# STM32L162 register map
File version: 1.3
CPU: CM3 r1p1, little endian, no MPU, no FPU, 4 interrupt priority bits
Registers are 32-bit, read-write, reset 0x0 unless marked. A register's access mark holds for its fields unless they carry their own. Offsets are from the block's base; [hi:lo] are bit positions; {n}, {i} and the like mark numbered series; 'fields as' and 'values as' point back to an identical list.

## DMA1 — Direct memory access controller
Base 0x40026000
Same registers: DMA2 0x40026400
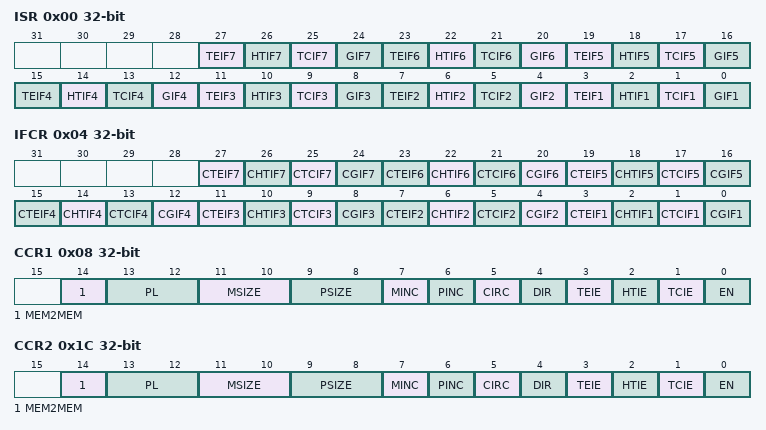
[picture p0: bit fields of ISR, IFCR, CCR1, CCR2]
0x00 ISR ro — interrupt status register
  [4n-1] TEIF{n} (n=1..7) — Channel x transfer error flag (x = 1 ..7)
  [4n-2] HTIF{n} (n=1..7) — Channel x half transfer flag (x = 1 ..7)
  [4n-3] TCIF{n} (n=1..7) — Channel x transfer complete flag (x = 1 ..7)
  [4n-4] GIF{n} (n=1..7) — Channel x global interrupt flag (x = 1 ..7)
0x04 IFCR wo — interrupt flag clear register
  [4n-1] CTEIF{n} (n=1..7) — Channel x transfer error clear (x = 1 ..7)
  [4n-2] CHTIF{n} (n=1..7) — Channel x half transfer clear (x = 1 ..7)
  [4n-3] CTCIF{n} (n=1..7) — Channel x transfer complete clear (x = 1 ..7)
  [4n-4] CGIF{n} (n=1..7) — Channel x global interrupt clear (x = 1 ..7)
0x08 CCR1 — channel x configuration register
  [14] MEM2MEM — Memory to memory mode
  [13:12] PL — Channel priority level
  [11:10] MSIZE — Memory size
  [9:8] PSIZE — Peripheral size
  [7] MINC — Memory increment mode
  [6] PINC — Peripheral increment mode
  [5] CIRC — Circular mode
  [4] DIR — Data transfer direction
  [3] TEIE — Transfer error interrupt enable
  [2] HTIE — Half transfer interrupt enable
  [1] TCIE — Transfer complete interrupt enable
  [0] EN — Channel enable
0x0C CNDTR1 — channel x number of data register
  [15:0] NDT — Number of data to transfer
0x10 CPAR1 — channel x peripheral address register
  [31:0] PA — Peripheral address
{0x0+0x14*i} CMAR{i} (i=1..7) — channel x memory address register
  [31:0] MA — Memory address
0x1C CCR2 — channel x configuration register
  fields as CCR1
0x20 CNDTR2 — channel x number of data register
  [15:0] NDT — Number of data to transfer
0x24 CPAR2 — channel x peripheral address register
  [31:0] PA — Peripheral address
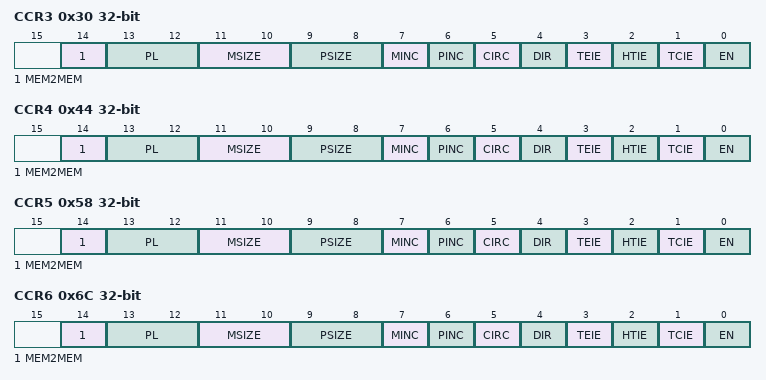
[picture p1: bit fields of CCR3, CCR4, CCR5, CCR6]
0x30 CCR3 — channel x configuration register
  fields as CCR1
0x34 CNDTR3 — channel x number of data register
  [15:0] NDT — Number of data to transfer
0x38 CPAR3 — channel x peripheral address register
  [31:0] PA — Peripheral address
0x44 CCR4 — channel x configuration register
  fields as CCR1
0x48 CNDTR4 — channel x number of data register
  [15:0] NDT — Number of data to transfer
0x4C CPAR4 — channel x peripheral address register
  [31:0] PA — Peripheral address
0x58 CCR5 — channel x configuration register
  fields as CCR1
0x5C CNDTR5 — channel x number of data register
  [15:0] NDT — Number of data to transfer
0x60 CPAR5 — channel x peripheral address register
  [31:0] PA — Peripheral address
0x6C CCR6 — channel x configuration register
  fields as CCR1
0x70 CNDTR6 — channel x number of data register
  [15:0] NDT — Number of data to transfer
0x74 CPAR6 — channel x peripheral address register
  [31:0] PA — Peripheral address
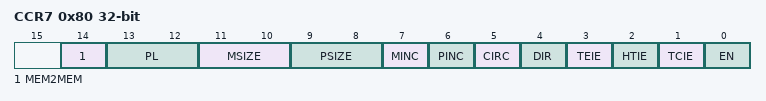
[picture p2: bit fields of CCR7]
0x80 CCR7 — channel x configuration register
  fields as CCR1
0x84 CNDTR7 — channel x number of data register
  [15:0] NDT — Number of data to transfer
0x88 CPAR7 — channel x peripheral address register
  [31:0] PA — Peripheral address

## EXTI — External interrupt/event controller
Base 0x40010400
0x00 IMR
  [22:0] MR — Interrupt mask on line x
0x04 EMR
  [22:0] MR — Event mask on line x
0x08 RTSR
  [22:0] TR — Rising edge trigger event configuration bit of line x
0x0C FTSR
  [22:0] TR — Falling edge trigger event configuration bit of line x
0x10 SWIER
  [22:0] SWIER — Software interrupt on line x
0x14 PR
  [22:0] PR — Pending bit

## Flash
Base 0x40023C00
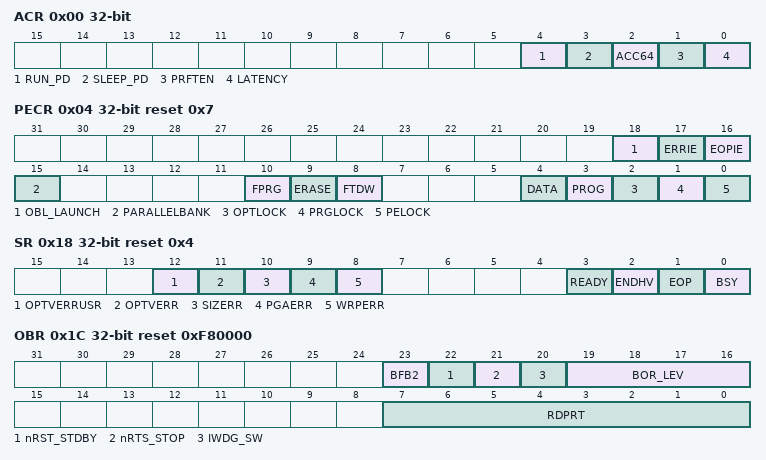
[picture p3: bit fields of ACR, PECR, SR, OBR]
0x00 ACR — Access control register
  [4] RUN_PD — Flash mode during Run
  [3] SLEEP_PD — Flash mode during Sleep
  [2] ACC64 — 64-bit access
  [1] PRFTEN — Prefetch enable
  [0] LATENCY
0x04 PECR reset 0x7 — Program/erase control register
  [18] OBL_LAUNCH — Launch the option byte loading
  [17] ERRIE — Error interrupt enable
  [16] EOPIE — End of programming interrupt enable
  [15] PARALLELBANK — Parallel bank mode
  [10] FPRG — Half Page/Double Word programming mode
  [9] ERASE — Page or Double Word erase mode
  [8] FTDW — Fixed time data write for Byte, Half Word and Word programming
  [4] DATA — Data EEPROM selection
  [3] PROG — Program memory selection
  [2] OPTLOCK — Option bytes block lock
  [1] PRGLOCK — Program memory lock
  [0] PELOCK — FLASH_PECR and data EEPROM lock
0x08 PDKEYR wo — Power down key register
  [31:0] PDKEYR — RUN_PD in FLASH_ACR key
0x0C PEKEYR wo — Program/erase key register
  [31:0] PEKEYR — FLASH_PEC and data EEPROM key
0x10 PRGKEYR wo — Program memory key register
  [31:0] PRGKEYR — Program memory key
0x14 OPTKEYR wo — Option byte key register
  [31:0] OPTKEYR — Option byte key
0x18 SR access per field reset 0x4 — Status register
  [12] OPTVERRUSR rw — Option UserValidity Error
  [11] OPTVERR rw — Option validity error
  [10] SIZERR rw — Size error
  [9] PGAERR rw — Programming alignment error
  [8] WRPERR rw — Write protected error
  [3] READY ro — Flash memory module ready after low power mode
  [2] ENDHV ro — End of high voltage
  [1] EOP ro — End of operation
  [0] BSY ro — Write/erase operations in progress
0x1C OBR ro reset 0xF80000 — Option byte register
  [23] BFB2 — Boot From Bank 2
  [22] nRST_STDBY
  [21] nRTS_STOP
  [20] IWDG_SW
  [19:16] BOR_LEV
  [7:0] RDPRT — Read protection
0x20 WRPR1 — Write protection register
  [31:0] WRP1 — Write protection
0x80 WRPR2 — Write protection register
  [31:0] WRP2
0x84 WRPR3 — Write protection register
  [31:0] WRP3
